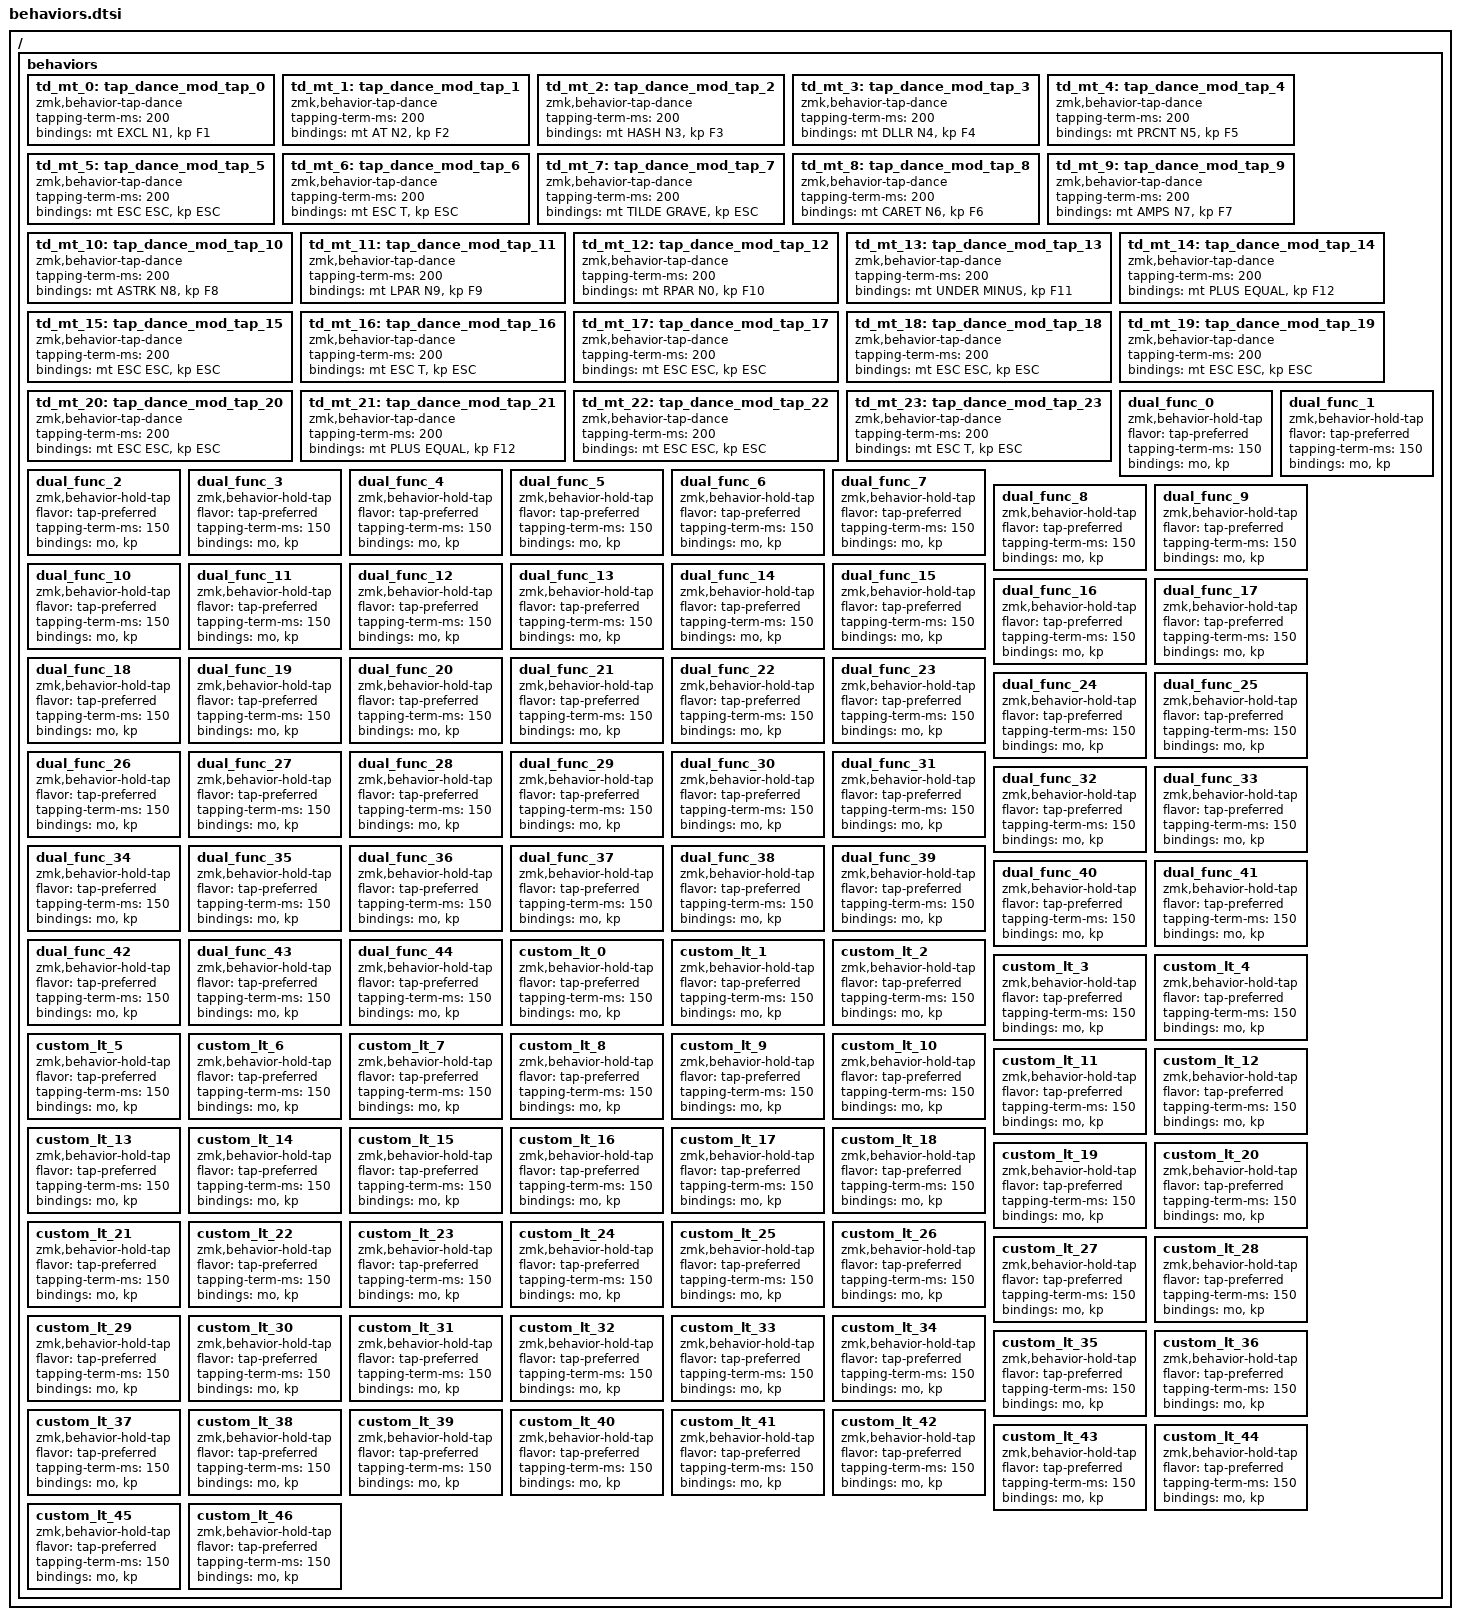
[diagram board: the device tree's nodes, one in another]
// Auto-generated by qmk_to_zmk.py - Complete behaviors conversion
#include <dt-bindings/zmk/keys.h>

/ {
    behaviors {
        td_mt_0: tap_dance_mod_tap_0 {
            compatible = "zmk,behavior-tap-dance";
            #binding-cells = <0>;
            tapping-term-ms = <200>;
            bindings = <&mt EXCL N1>, <&kp F1>;
        };

        td_mt_1: tap_dance_mod_tap_1 {
            compatible = "zmk,behavior-tap-dance";
            #binding-cells = <0>;
            tapping-term-ms = <200>;
            bindings = <&mt AT N2>, <&kp F2>;
        };

        td_mt_2: tap_dance_mod_tap_2 {
            compatible = "zmk,behavior-tap-dance";
            #binding-cells = <0>;
            tapping-term-ms = <200>;
            bindings = <&mt HASH N3>, <&kp F3>;
        };

        td_mt_3: tap_dance_mod_tap_3 {
            compatible = "zmk,behavior-tap-dance";
            #binding-cells = <0>;
            tapping-term-ms = <200>;
            bindings = <&mt DLLR N4>, <&kp F4>;
        };

        td_mt_4: tap_dance_mod_tap_4 {
            compatible = "zmk,behavior-tap-dance";
            #binding-cells = <0>;
            tapping-term-ms = <200>;
            bindings = <&mt PRCNT N5>, <&kp F5>;
        };

        td_mt_5: tap_dance_mod_tap_5 {
            compatible = "zmk,behavior-tap-dance";
            #binding-cells = <0>;
            tapping-term-ms = <200>;
            bindings = <&mt ESC ESC>, <&kp ESC>;
        };

        td_mt_6: tap_dance_mod_tap_6 {
            compatible = "zmk,behavior-tap-dance";
            #binding-cells = <0>;
            tapping-term-ms = <200>;
            bindings = <&mt ESC T>, <&kp ESC>;
        };

        td_mt_7: tap_dance_mod_tap_7 {
            compatible = "zmk,behavior-tap-dance";
            #binding-cells = <0>;
            tapping-term-ms = <200>;
            bindings = <&mt TILDE GRAVE>, <&kp ESC>;
        };

        td_mt_8: tap_dance_mod_tap_8 {
            compatible = "zmk,behavior-tap-dance";
            #binding-cells = <0>;
            tapping-term-ms = <200>;
            bindings = <&mt CARET N6>, <&kp F6>;
        };

        td_mt_9: tap_dance_mod_tap_9 {
            compatible = "zmk,behavior-tap-dance";
            #binding-cells = <0>;
            tapping-term-ms = <200>;
            bindings = <&mt AMPS N7>, <&kp F7>;
        };

        td_mt_10: tap_dance_mod_tap_10 {
            compatible = "zmk,behavior-tap-dance";
            #binding-cells = <0>;
            tapping-term-ms = <200>;
            bindings = <&mt ASTRK N8>, <&kp F8>;
        };

        td_mt_11: tap_dance_mod_tap_11 {
            compatible = "zmk,behavior-tap-dance";
            #binding-cells = <0>;
            tapping-term-ms = <200>;
            bindings = <&mt LPAR N9>, <&kp F9>;
        };

        td_mt_12: tap_dance_mod_tap_12 {
            compatible = "zmk,behavior-tap-dance";
            #binding-cells = <0>;
            tapping-term-ms = <200>;
            bindings = <&mt RPAR N0>, <&kp F10>;
        };

        td_mt_13: tap_dance_mod_tap_13 {
            compatible = "zmk,behavior-tap-dance";
            #binding-cells = <0>;
            tapping-term-ms = <200>;
            bindings = <&mt UNDER MINUS>, <&kp F11>;
        };

        td_mt_14: tap_dance_mod_tap_14 {
            compatible = "zmk,behavior-tap-dance";
            #binding-cells = <0>;
            tapping-term-ms = <200>;
            bindings = <&mt PLUS EQUAL>, <&kp F12>;
        };

        td_mt_15: tap_dance_mod_tap_15 {
            compatible = "zmk,behavior-tap-dance";
            #binding-cells = <0>;
            tapping-term-ms = <200>;
            bindings = <&mt ESC ESC>, <&kp ESC>;
        };

        td_mt_16: tap_dance_mod_tap_16 {
            compatible = "zmk,behavior-tap-dance";
            #binding-cells = <0>;
            tapping-term-ms = <200>;
            bindings = <&mt ESC T>, <&kp ESC>;
        };

        td_mt_17: tap_dance_mod_tap_17 {
            compatible = "zmk,behavior-tap-dance";
            #binding-cells = <0>;
            tapping-term-ms = <200>;
            bindings = <&mt ESC ESC>, <&kp ESC>;
        };

        td_mt_18: tap_dance_mod_tap_18 {
            compatible = "zmk,behavior-tap-dance";
            #binding-cells = <0>;
            tapping-term-ms = <200>;
            bindings = <&mt ESC ESC>, <&kp ESC>;
        };

        td_mt_19: tap_dance_mod_tap_19 {
            compatible = "zmk,behavior-tap-dance";
            #binding-cells = <0>;
            tapping-term-ms = <200>;
            bindings = <&mt ESC ESC>, <&kp ESC>;
        };

        td_mt_20: tap_dance_mod_tap_20 {
            compatible = "zmk,behavior-tap-dance";
            #binding-cells = <0>;
            tapping-term-ms = <200>;
            bindings = <&mt ESC ESC>, <&kp ESC>;
        };

        td_mt_21: tap_dance_mod_tap_21 {
            compatible = "zmk,behavior-tap-dance";
            #binding-cells = <0>;
            tapping-term-ms = <200>;
            bindings = <&mt PLUS EQUAL>, <&kp F12>;
        };

        td_mt_22: tap_dance_mod_tap_22 {
            compatible = "zmk,behavior-tap-dance";
            #binding-cells = <0>;
            tapping-term-ms = <200>;
            bindings = <&mt ESC ESC>, <&kp ESC>;
        };

        td_mt_23: tap_dance_mod_tap_23 {
            compatible = "zmk,behavior-tap-dance";
            #binding-cells = <0>;
            tapping-term-ms = <200>;
            bindings = <&mt ESC T>, <&kp ESC>;
        };

        dual_func_0: dual_func_0 {
            compatible = "zmk,behavior-hold-tap";
            #binding-cells = <2>;
            flavor = "tap-preferred";
            tapping-term-ms = <150>;
            bindings = <&mo>, <&kp>;
        };

        dual_func_1: dual_func_1 {
            compatible = "zmk,behavior-hold-tap";
            #binding-cells = <2>;
            flavor = "tap-preferred";
            tapping-term-ms = <150>;
            bindings = <&mo>, <&kp>;
        };

        dual_func_2: dual_func_2 {
            compatible = "zmk,behavior-hold-tap";
            #binding-cells = <2>;
            flavor = "tap-preferred";
            tapping-term-ms = <150>;
            bindings = <&mo>, <&kp>;
        };

        dual_func_3: dual_func_3 {
            compatible = "zmk,behavior-hold-tap";
            #binding-cells = <2>;
            flavor = "tap-preferred";
            tapping-term-ms = <150>;
            bindings = <&mo>, <&kp>;
        };

        dual_func_4: dual_func_4 {
            compatible = "zmk,behavior-hold-tap";
            #binding-cells = <2>;
            flavor = "tap-preferred";
            tapping-term-ms = <150>;
            bindings = <&mo>, <&kp>;
        };

        dual_func_5: dual_func_5 {
            compatible = "zmk,behavior-hold-tap";
            #binding-cells = <2>;
            flavor = "tap-preferred";
            tapping-term-ms = <150>;
            bindings = <&mo>, <&kp>;
        };

        dual_func_6: dual_func_6 {
            compatible = "zmk,behavior-hold-tap";
            #binding-cells = <2>;
            flavor = "tap-preferred";
            tapping-term-ms = <150>;
            bindings = <&mo>, <&kp>;
        };

        dual_func_7: dual_func_7 {
            compatible = "zmk,behavior-hold-tap";
            #binding-cells = <2>;
            flavor = "tap-preferred";
            tapping-term-ms = <150>;
            bindings = <&mo>, <&kp>;
        };

        dual_func_8: dual_func_8 {
            compatible = "zmk,behavior-hold-tap";
            #binding-cells = <2>;
            flavor = "tap-preferred";
            tapping-term-ms = <150>;
            bindings = <&mo>, <&kp>;
        };

        dual_func_9: dual_func_9 {
            compatible = "zmk,behavior-hold-tap";
            #binding-cells = <2>;
            flavor = "tap-preferred";
            tapping-term-ms = <150>;
            bindings = <&mo>, <&kp>;
        };

        dual_func_10: dual_func_10 {
            compatible = "zmk,behavior-hold-tap";
            #binding-cells = <2>;
            flavor = "tap-preferred";
            tapping-term-ms = <150>;
            bindings = <&mo>, <&kp>;
        };

        dual_func_11: dual_func_11 {
            compatible = "zmk,behavior-hold-tap";
            #binding-cells = <2>;
            flavor = "tap-preferred";
            tapping-term-ms = <150>;
            bindings = <&mo>, <&kp>;
        };

        dual_func_12: dual_func_12 {
            compatible = "zmk,behavior-hold-tap";
            #binding-cells = <2>;
            flavor = "tap-preferred";
            tapping-term-ms = <150>;
            bindings = <&mo>, <&kp>;
        };

        dual_func_13: dual_func_13 {
            compatible = "zmk,behavior-hold-tap";
            #binding-cells = <2>;
            flavor = "tap-preferred";
            tapping-term-ms = <150>;
            bindings = <&mo>, <&kp>;
        };

        dual_func_14: dual_func_14 {
            compatible = "zmk,behavior-hold-tap";
            #binding-cells = <2>;
            flavor = "tap-preferred";
            tapping-term-ms = <150>;
            bindings = <&mo>, <&kp>;
        };

        dual_func_15: dual_func_15 {
            compatible = "zmk,behavior-hold-tap";
            #binding-cells = <2>;
            flavor = "tap-preferred";
            tapping-term-ms = <150>;
            bindings = <&mo>, <&kp>;
        };

        dual_func_16: dual_func_16 {
            compatible = "zmk,behavior-hold-tap";
            #binding-cells = <2>;
            flavor = "tap-preferred";
            tapping-term-ms = <150>;
            bindings = <&mo>, <&kp>;
        };

        dual_func_17: dual_func_17 {
            compatible = "zmk,behavior-hold-tap";
            #binding-cells = <2>;
            flavor = "tap-preferred";
            tapping-term-ms = <150>;
            bindings = <&mo>, <&kp>;
        };

        dual_func_18: dual_func_18 {
            compatible = "zmk,behavior-hold-tap";
            #binding-cells = <2>;
            flavor = "tap-preferred";
            tapping-term-ms = <150>;
            bindings = <&mo>, <&kp>;
        };

        dual_func_19: dual_func_19 {
            compatible = "zmk,behavior-hold-tap";
            #binding-cells = <2>;
            flavor = "tap-preferred";
            tapping-term-ms = <150>;
            bindings = <&mo>, <&kp>;
        };

        dual_func_20: dual_func_20 {
            compatible = "zmk,behavior-hold-tap";
            #binding-cells = <2>;
            flavor = "tap-preferred";
            tapping-term-ms = <150>;
            bindings = <&mo>, <&kp>;
        };

        dual_func_21: dual_func_21 {
            compatible = "zmk,behavior-hold-tap";
            #binding-cells = <2>;
            flavor = "tap-preferred";
            tapping-term-ms = <150>;
            bindings = <&mo>, <&kp>;
        };

        dual_func_22: dual_func_22 {
            compatible = "zmk,behavior-hold-tap";
            #binding-cells = <2>;
            flavor = "tap-preferred";
            tapping-term-ms = <150>;
            bindings = <&mo>, <&kp>;
        };

        dual_func_23: dual_func_23 {
            compatible = "zmk,behavior-hold-tap";
            #binding-cells = <2>;
            flavor = "tap-preferred";
            tapping-term-ms = <150>;
            bindings = <&mo>, <&kp>;
        };

        dual_func_24: dual_func_24 {
            compatible = "zmk,behavior-hold-tap";
            #binding-cells = <2>;
            flavor = "tap-preferred";
            tapping-term-ms = <150>;
            bindings = <&mo>, <&kp>;
        };

        dual_func_25: dual_func_25 {
            compatible = "zmk,behavior-hold-tap";
            #binding-cells = <2>;
            flavor = "tap-preferred";
            tapping-term-ms = <150>;
            bindings = <&mo>, <&kp>;
        };

        dual_func_26: dual_func_26 {
            compatible = "zmk,behavior-hold-tap";
            #binding-cells = <2>;
            flavor = "tap-preferred";
            tapping-term-ms = <150>;
            bindings = <&mo>, <&kp>;
        };

        dual_func_27: dual_func_27 {
            compatible = "zmk,behavior-hold-tap";
            #binding-cells = <2>;
            flavor = "tap-preferred";
            tapping-term-ms = <150>;
            bindings = <&mo>, <&kp>;
        };

        dual_func_28: dual_func_28 {
            compatible = "zmk,behavior-hold-tap";
            #binding-cells = <2>;
            flavor = "tap-preferred";
            tapping-term-ms = <150>;
            bindings = <&mo>, <&kp>;
        };

        dual_func_29: dual_func_29 {
            compatible = "zmk,behavior-hold-tap";
            #binding-cells = <2>;
            flavor = "tap-preferred";
            tapping-term-ms = <150>;
            bindings = <&mo>, <&kp>;
        };

        dual_func_30: dual_func_30 {
            compatible = "zmk,behavior-hold-tap";
            #binding-cells = <2>;
            flavor = "tap-preferred";
            tapping-term-ms = <150>;
            bindings = <&mo>, <&kp>;
        };

        dual_func_31: dual_func_31 {
            compatible = "zmk,behavior-hold-tap";
            #binding-cells = <2>;
            flavor = "tap-preferred";
            tapping-term-ms = <150>;
            bindings = <&mo>, <&kp>;
        };

        dual_func_32: dual_func_32 {
            compatible = "zmk,behavior-hold-tap";
            #binding-cells = <2>;
            flavor = "tap-preferred";
            tapping-term-ms = <150>;
            bindings = <&mo>, <&kp>;
        };

        dual_func_33: dual_func_33 {
            compatible = "zmk,behavior-hold-tap";
            #binding-cells = <2>;
            flavor = "tap-preferred";
            tapping-term-ms = <150>;
            bindings = <&mo>, <&kp>;
        };

        dual_func_34: dual_func_34 {
            compatible = "zmk,behavior-hold-tap";
            #binding-cells = <2>;
            flavor = "tap-preferred";
            tapping-term-ms = <150>;
            bindings = <&mo>, <&kp>;
        };

        dual_func_35: dual_func_35 {
            compatible = "zmk,behavior-hold-tap";
            #binding-cells = <2>;
            flavor = "tap-preferred";
            tapping-term-ms = <150>;
            bindings = <&mo>, <&kp>;
        };

        dual_func_36: dual_func_36 {
            compatible = "zmk,behavior-hold-tap";
            #binding-cells = <2>;
            flavor = "tap-preferred";
            tapping-term-ms = <150>;
            bindings = <&mo>, <&kp>;
        };

        dual_func_37: dual_func_37 {
            compatible = "zmk,behavior-hold-tap";
            #binding-cells = <2>;
            flavor = "tap-preferred";
            tapping-term-ms = <150>;
            bindings = <&mo>, <&kp>;
        };

        dual_func_38: dual_func_38 {
            compatible = "zmk,behavior-hold-tap";
            #binding-cells = <2>;
            flavor = "tap-preferred";
            tapping-term-ms = <150>;
            bindings = <&mo>, <&kp>;
        };

        dual_func_39: dual_func_39 {
            compatible = "zmk,behavior-hold-tap";
            #binding-cells = <2>;
            flavor = "tap-preferred";
            tapping-term-ms = <150>;
            bindings = <&mo>, <&kp>;
        };

        dual_func_40: dual_func_40 {
            compatible = "zmk,behavior-hold-tap";
            #binding-cells = <2>;
            flavor = "tap-preferred";
            tapping-term-ms = <150>;
            bindings = <&mo>, <&kp>;
        };

        dual_func_41: dual_func_41 {
            compatible = "zmk,behavior-hold-tap";
            #binding-cells = <2>;
            flavor = "tap-preferred";
            tapping-term-ms = <150>;
            bindings = <&mo>, <&kp>;
        };

        dual_func_42: dual_func_42 {
            compatible = "zmk,behavior-hold-tap";
            #binding-cells = <2>;
            flavor = "tap-preferred";
            tapping-term-ms = <150>;
            bindings = <&mo>, <&kp>;
        };

        dual_func_43: dual_func_43 {
            compatible = "zmk,behavior-hold-tap";
            #binding-cells = <2>;
            flavor = "tap-preferred";
            tapping-term-ms = <150>;
            bindings = <&mo>, <&kp>;
        };

        dual_func_44: dual_func_44 {
            compatible = "zmk,behavior-hold-tap";
            #binding-cells = <2>;
            flavor = "tap-preferred";
            tapping-term-ms = <150>;
            bindings = <&mo>, <&kp>;
        };

        custom_lt_0: custom_lt_0 {
            compatible = "zmk,behavior-hold-tap";
            #binding-cells = <2>;
            flavor = "tap-preferred";
            tapping-term-ms = <150>;
            bindings = <&mo>, <&kp>;
        };

        custom_lt_1: custom_lt_1 {
            compatible = "zmk,behavior-hold-tap";
            #binding-cells = <2>;
            flavor = "tap-preferred";
            tapping-term-ms = <150>;
            bindings = <&mo>, <&kp>;
        };

        custom_lt_2: custom_lt_2 {
            compatible = "zmk,behavior-hold-tap";
            #binding-cells = <2>;
            flavor = "tap-preferred";
            tapping-term-ms = <150>;
            bindings = <&mo>, <&kp>;
        };

        custom_lt_3: custom_lt_3 {
            compatible = "zmk,behavior-hold-tap";
            #binding-cells = <2>;
            flavor = "tap-preferred";
            tapping-term-ms = <150>;
            bindings = <&mo>, <&kp>;
        };

        custom_lt_4: custom_lt_4 {
            compatible = "zmk,behavior-hold-tap";
            #binding-cells = <2>;
            flavor = "tap-preferred";
            tapping-term-ms = <150>;
            bindings = <&mo>, <&kp>;
        };

        custom_lt_5: custom_lt_5 {
            compatible = "zmk,behavior-hold-tap";
            #binding-cells = <2>;
            flavor = "tap-preferred";
            tapping-term-ms = <150>;
            bindings = <&mo>, <&kp>;
        };

        custom_lt_6: custom_lt_6 {
            compatible = "zmk,behavior-hold-tap";
            #binding-cells = <2>;
            flavor = "tap-preferred";
            tapping-term-ms = <150>;
            bindings = <&mo>, <&kp>;
        };

        custom_lt_7: custom_lt_7 {
            compatible = "zmk,behavior-hold-tap";
            #binding-cells = <2>;
            flavor = "tap-preferred";
            tapping-term-ms = <150>;
            bindings = <&mo>, <&kp>;
        };

        custom_lt_8: custom_lt_8 {
            compatible = "zmk,behavior-hold-tap";
            #binding-cells = <2>;
            flavor = "tap-preferred";
            tapping-term-ms = <150>;
            bindings = <&mo>, <&kp>;
        };

        custom_lt_9: custom_lt_9 {
            compatible = "zmk,behavior-hold-tap";
            #binding-cells = <2>;
            flavor = "tap-preferred";
            tapping-term-ms = <150>;
            bindings = <&mo>, <&kp>;
        };

        custom_lt_10: custom_lt_10 {
            compatible = "zmk,behavior-hold-tap";
            #binding-cells = <2>;
            flavor = "tap-preferred";
            tapping-term-ms = <150>;
            bindings = <&mo>, <&kp>;
        };

        custom_lt_11: custom_lt_11 {
            compatible = "zmk,behavior-hold-tap";
            #binding-cells = <2>;
            flavor = "tap-preferred";
            tapping-term-ms = <150>;
            bindings = <&mo>, <&kp>;
        };

        custom_lt_12: custom_lt_12 {
            compatible = "zmk,behavior-hold-tap";
            #binding-cells = <2>;
            flavor = "tap-preferred";
            tapping-term-ms = <150>;
            bindings = <&mo>, <&kp>;
        };

        custom_lt_13: custom_lt_13 {
            compatible = "zmk,behavior-hold-tap";
            #binding-cells = <2>;
            flavor = "tap-preferred";
            tapping-term-ms = <150>;
            bindings = <&mo>, <&kp>;
        };

        custom_lt_14: custom_lt_14 {
            compatible = "zmk,behavior-hold-tap";
            #binding-cells = <2>;
            flavor = "tap-preferred";
            tapping-term-ms = <150>;
            bindings = <&mo>, <&kp>;
        };

        custom_lt_15: custom_lt_15 {
            compatible = "zmk,behavior-hold-tap";
            #binding-cells = <2>;
            flavor = "tap-preferred";
            tapping-term-ms = <150>;
            bindings = <&mo>, <&kp>;
        };

        custom_lt_16: custom_lt_16 {
            compatible = "zmk,behavior-hold-tap";
            #binding-cells = <2>;
            flavor = "tap-preferred";
            tapping-term-ms = <150>;
            bindings = <&mo>, <&kp>;
        };

        custom_lt_17: custom_lt_17 {
            compatible = "zmk,behavior-hold-tap";
            #binding-cells = <2>;
            flavor = "tap-preferred";
            tapping-term-ms = <150>;
            bindings = <&mo>, <&kp>;
        };

        custom_lt_18: custom_lt_18 {
            compatible = "zmk,behavior-hold-tap";
            #binding-cells = <2>;
            flavor = "tap-preferred";
            tapping-term-ms = <150>;
            bindings = <&mo>, <&kp>;
        };

        custom_lt_19: custom_lt_19 {
            compatible = "zmk,behavior-hold-tap";
            #binding-cells = <2>;
            flavor = "tap-preferred";
            tapping-term-ms = <150>;
            bindings = <&mo>, <&kp>;
        };

        custom_lt_20: custom_lt_20 {
            compatible = "zmk,behavior-hold-tap";
            #binding-cells = <2>;
            flavor = "tap-preferred";
            tapping-term-ms = <150>;
            bindings = <&mo>, <&kp>;
        };

        custom_lt_21: custom_lt_21 {
            compatible = "zmk,behavior-hold-tap";
            #binding-cells = <2>;
            flavor = "tap-preferred";
            tapping-term-ms = <150>;
            bindings = <&mo>, <&kp>;
        };

        custom_lt_22: custom_lt_22 {
            compatible = "zmk,behavior-hold-tap";
            #binding-cells = <2>;
            flavor = "tap-preferred";
            tapping-term-ms = <150>;
            bindings = <&mo>, <&kp>;
        };

        custom_lt_23: custom_lt_23 {
            compatible = "zmk,behavior-hold-tap";
            #binding-cells = <2>;
            flavor = "tap-preferred";
            tapping-term-ms = <150>;
            bindings = <&mo>, <&kp>;
        };

        custom_lt_24: custom_lt_24 {
            compatible = "zmk,behavior-hold-tap";
            #binding-cells = <2>;
            flavor = "tap-preferred";
            tapping-term-ms = <150>;
            bindings = <&mo>, <&kp>;
        };

        custom_lt_25: custom_lt_25 {
            compatible = "zmk,behavior-hold-tap";
            #binding-cells = <2>;
            flavor = "tap-preferred";
            tapping-term-ms = <150>;
            bindings = <&mo>, <&kp>;
        };

        custom_lt_26: custom_lt_26 {
            compatible = "zmk,behavior-hold-tap";
            #binding-cells = <2>;
            flavor = "tap-preferred";
            tapping-term-ms = <150>;
            bindings = <&mo>, <&kp>;
        };

        custom_lt_27: custom_lt_27 {
            compatible = "zmk,behavior-hold-tap";
            #binding-cells = <2>;
            flavor = "tap-preferred";
            tapping-term-ms = <150>;
            bindings = <&mo>, <&kp>;
        };

        custom_lt_28: custom_lt_28 {
            compatible = "zmk,behavior-hold-tap";
            #binding-cells = <2>;
            flavor = "tap-preferred";
            tapping-term-ms = <150>;
            bindings = <&mo>, <&kp>;
        };

        custom_lt_29: custom_lt_29 {
            compatible = "zmk,behavior-hold-tap";
            #binding-cells = <2>;
            flavor = "tap-preferred";
            tapping-term-ms = <150>;
            bindings = <&mo>, <&kp>;
        };

        custom_lt_30: custom_lt_30 {
            compatible = "zmk,behavior-hold-tap";
            #binding-cells = <2>;
            flavor = "tap-preferred";
            tapping-term-ms = <150>;
            bindings = <&mo>, <&kp>;
        };

        custom_lt_31: custom_lt_31 {
            compatible = "zmk,behavior-hold-tap";
            #binding-cells = <2>;
            flavor = "tap-preferred";
            tapping-term-ms = <150>;
            bindings = <&mo>, <&kp>;
        };

        custom_lt_32: custom_lt_32 {
            compatible = "zmk,behavior-hold-tap";
            #binding-cells = <2>;
            flavor = "tap-preferred";
            tapping-term-ms = <150>;
            bindings = <&mo>, <&kp>;
        };

        custom_lt_33: custom_lt_33 {
            compatible = "zmk,behavior-hold-tap";
            #binding-cells = <2>;
            flavor = "tap-preferred";
            tapping-term-ms = <150>;
            bindings = <&mo>, <&kp>;
        };

        custom_lt_34: custom_lt_34 {
            compatible = "zmk,behavior-hold-tap";
            #binding-cells = <2>;
            flavor = "tap-preferred";
            tapping-term-ms = <150>;
            bindings = <&mo>, <&kp>;
        };

        custom_lt_35: custom_lt_35 {
            compatible = "zmk,behavior-hold-tap";
            #binding-cells = <2>;
            flavor = "tap-preferred";
            tapping-term-ms = <150>;
            bindings = <&mo>, <&kp>;
        };

        custom_lt_36: custom_lt_36 {
            compatible = "zmk,behavior-hold-tap";
            #binding-cells = <2>;
            flavor = "tap-preferred";
            tapping-term-ms = <150>;
            bindings = <&mo>, <&kp>;
        };

        custom_lt_37: custom_lt_37 {
            compatible = "zmk,behavior-hold-tap";
            #binding-cells = <2>;
            flavor = "tap-preferred";
            tapping-term-ms = <150>;
            bindings = <&mo>, <&kp>;
        };

        custom_lt_38: custom_lt_38 {
            compatible = "zmk,behavior-hold-tap";
            #binding-cells = <2>;
            flavor = "tap-preferred";
            tapping-term-ms = <150>;
            bindings = <&mo>, <&kp>;
        };

        custom_lt_39: custom_lt_39 {
            compatible = "zmk,behavior-hold-tap";
            #binding-cells = <2>;
            flavor = "tap-preferred";
            tapping-term-ms = <150>;
            bindings = <&mo>, <&kp>;
        };

        custom_lt_40: custom_lt_40 {
            compatible = "zmk,behavior-hold-tap";
            #binding-cells = <2>;
            flavor = "tap-preferred";
            tapping-term-ms = <150>;
            bindings = <&mo>, <&kp>;
        };

        custom_lt_41: custom_lt_41 {
            compatible = "zmk,behavior-hold-tap";
            #binding-cells = <2>;
            flavor = "tap-preferred";
            tapping-term-ms = <150>;
            bindings = <&mo>, <&kp>;
        };

        custom_lt_42: custom_lt_42 {
            compatible = "zmk,behavior-hold-tap";
            #binding-cells = <2>;
            flavor = "tap-preferred";
            tapping-term-ms = <150>;
            bindings = <&mo>, <&kp>;
        };

        custom_lt_43: custom_lt_43 {
            compatible = "zmk,behavior-hold-tap";
            #binding-cells = <2>;
            flavor = "tap-preferred";
            tapping-term-ms = <150>;
            bindings = <&mo>, <&kp>;
        };

        custom_lt_44: custom_lt_44 {
            compatible = "zmk,behavior-hold-tap";
            #binding-cells = <2>;
            flavor = "tap-preferred";
            tapping-term-ms = <150>;
            bindings = <&mo>, <&kp>;
        };

        custom_lt_45: custom_lt_45 {
            compatible = "zmk,behavior-hold-tap";
            #binding-cells = <2>;
            flavor = "tap-preferred";
            tapping-term-ms = <150>;
            bindings = <&mo>, <&kp>;
        };

        custom_lt_46: custom_lt_46 {
            compatible = "zmk,behavior-hold-tap";
            #binding-cells = <2>;
            flavor = "tap-preferred";
            tapping-term-ms = <150>;
            bindings = <&mo>, <&kp>;
        };

    };
};
